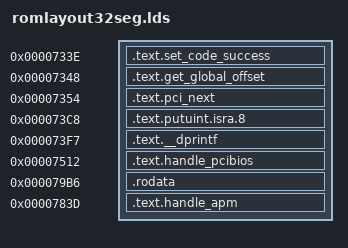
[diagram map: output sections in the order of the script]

/* DO NOT EDIT!  This is an autogenerated file.  See scripts/layoutrom.py. */
OUTPUT_FORMAT("elf32-i386")
OUTPUT_ARCH("i386")
SECTIONS
{
MaxPCIBus = 0x6e44 ;
PirAddr = 0x6da4 ;
entry_pcibios32 = 0xd1d5 ;
entry_apm16 = 0xd162 ;
entry_apm32 = 0xd1a3 ;
acpi_pm1a_cnt = 0x6da0 ;
.text.set_code_success 0x733e : { *(.text.set_code_success) }
.text.get_global_offset 0x7348 : { *(.text.get_global_offset) }
.text.pci_next 0x7354 : { *(.text.pci_next) }
.text.putuint.isra.8 0x73c8 : { *(.text.putuint.isra.8) }
.text.__dprintf 0x73f7 : { *(.text.__dprintf) }
.text.handle_pcibios 0x7512 : { *(.text.handle_pcibios) }
.rodata 0x79b6 : { *(.rodata) }
.text.handle_apm 0x783d : { *(.text.handle_apm) }


        /* Discard regular data sections to force a link error if
         * code attempts to access data not marked with VAR16 (or other
         * appropriate macro)
         */
        /DISCARD/ : {
                *(.text*) *(.data*) *(.bss*) *(.rodata*)
                *(COMMON) *(.discard*) *(.eh_frame) *(.note*)
                }
}
